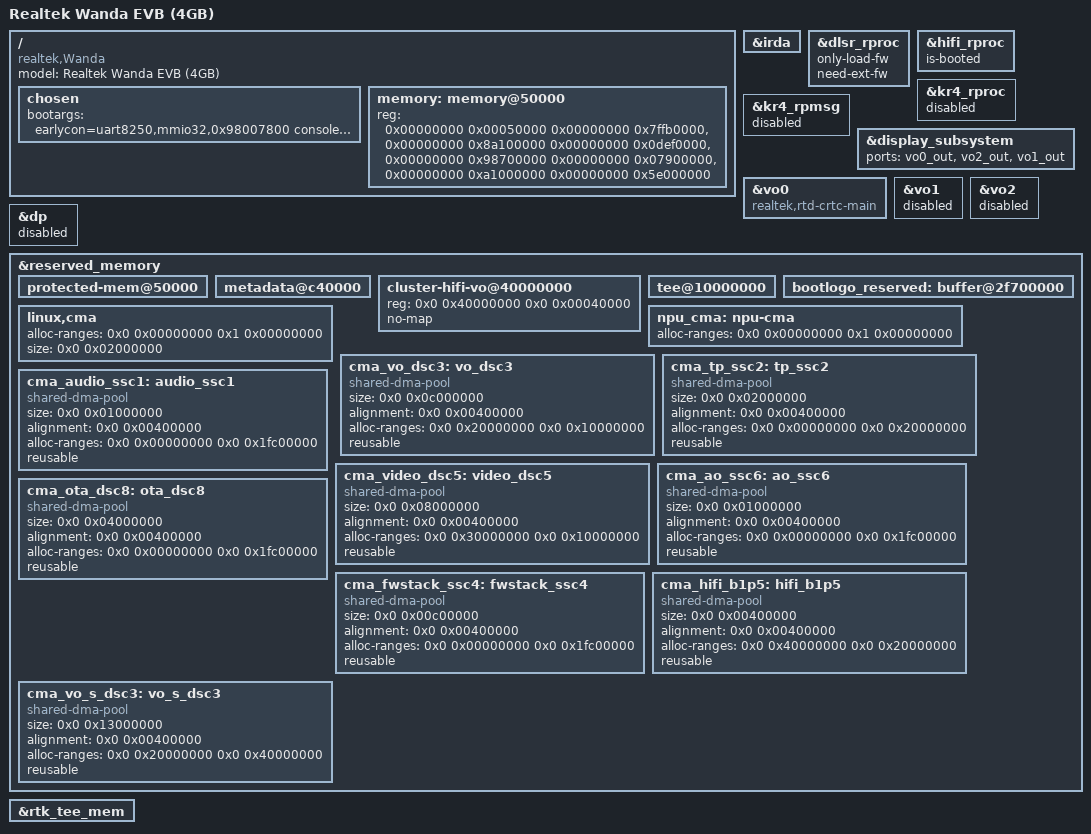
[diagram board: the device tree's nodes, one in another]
// SPDX-License-Identifier: (GPL-2.0-or-later OR BSD-2-Clause)
/*
 * Realtek RTD1635S Wanda EVB
 *
 * Copyright (c) 2025 Realtek Semiconductor Corp.
 */

/dts-v1/;

#include "rtd1635s-wanda.dtsi"

/ {
	compatible = "realtek,Wanda", "realtek,rtd1635s";
	model = "Realtek Wanda EVB (4GB)";
	chosen {
		bootargs = "earlycon=uart8250,mmio32,0x98007800 console=ttyS0,460800 8250.nr_uarts=2 init=/init loglevel=8 max_loop=64 loop.max_part=7 firmware_class.path=/vendor/firmware/,/vendor/av_fw";
	};

	memory: memory@50000 {
		device_type = "memory";
		reg = <0x00000000 0x00050000 0x00000000 0x7ffb0000>,
		      <0x00000000 0x8a100000 0x00000000 0x0def0000>,
		      <0x00000000 0x98700000 0x00000000 0x07900000>,
		      <0x00000000 0xa1000000 0x00000000 0x5e000000>;
	};
};

&irda {
	status = "okay";
};

&dlsr_rproc {
	only-load-fw;
	need-ext-fw;
	status = "okay";
};

&hifi_rproc {
	is-booted;
	status = "okay";
};

&kr4_rproc {
	status = "disabled";
};

&kr4_rpmsg {
	status = "disabled";
};

&display_subsystem {
	status = "okay";
	ports = <&vo0_out>, <&vo2_out>, <&vo1_out>;
};

&vo0 {
	compatible = "realtek,rtd-crtc-main";
	status = "okay";
};

&vo1 {
	status = "disabled";
};

&vo2 {
	status = "disabled";
};

&dp {
	status = "disabled";
};

&reserved_memory {
	protected-mem@50000 {
		status = "okay";
	};

	metadata@c40000 {
		status = "okay";
	};

	cluster-hifi-vo@40000000 {
		reg = <0x0 0x40000000 0x0 0x00040000>;  /* Cluster to Hifi vo 256kb */
		no-map;
	};

	tee@10000000 {
		status = "okay";
	};

	bootlogo_reserved: buffer@2f700000 {
		status = "okay";
	};

	linux,cma {
		alloc-ranges=<0x0 0x00000000 0x1 0x00000000>;
		size = <0x0 0x02000000>; /* 32M */
	};

	npu_cma: npu-cma {
		alloc-ranges=<0x0 0x00000000 0x1 0x00000000>;
		status = "okay";
	};

	cma_vo_dsc3:vo_dsc3 {
		compatible = "shared-dma-pool";
		size = <0x0 0x0c000000>;		    /* 192M */
		alignment = <0x0 0x00400000>;

		/* Avoid crossing A/VCPU PA2VA per 512M boundary */
		/* Avoid allocating 0x1fc00000 ~ 0x1fc00fff to LX CPU (A/VCPU/VE3) */
		alloc-ranges=<0x0 0x20000000 0x0 0x10000000>;
		reusable;
	};

	cma_tp_ssc2:tp_ssc2 {
		compatible = "shared-dma-pool";
		size = <0x0 0x02000000>;		    /* 32M */
		alignment = <0x0 0x00400000>;
		alloc-ranges=<0x0 0x00000000 0x0 0x20000000>;
		reusable;
	};

	cma_audio_ssc1:audio_ssc1 {
		compatible = "shared-dma-pool";
		size = <0x0 0x01000000>;		    /* 16M */
		alignment = <0x0 0x00400000>;

		/* Avoid crossing A/VCPU PA2VA per 512M boundary */
		/* Avoid allocating 0x1fc00000 ~ 0x1fc00fff to LX CPU (A/VCPU/VE3) */
		alloc-ranges=<0x0 0x00000000 0x0 0x1fc00000>;
		reusable;
	};

	cma_video_dsc5:video_dsc5 {
		compatible = "shared-dma-pool";
		size = <0x0 0x08000000>;		    /* 128M */
		alignment = <0x0 0x00400000>;

		/* Avoid crossing A/VCPU PA2VA per 512M boundary */
		/* Avoid allocating 0x1fc00000 ~ 0x1fc00fff to LX CPU (A/VCPU/VE3) */
		alloc-ranges=<0x0 0x30000000 0x0 0x10000000>;
		reusable;
	};

	cma_ao_ssc6:ao_ssc6 {
		compatible = "shared-dma-pool";
		size = <0x0 0x01000000>;		    /* 16M */
		alignment = <0x0 0x00400000>;

		/* Avoid crossing A/VCPU PA2VA per 512M boundary */
		/* Avoid allocating 0x1fc00000 ~ 0x1fc00fff to LX CPU (A/VCPU/VE3) */
		alloc-ranges=<0x0 0x00000000 0x0 0x1fc00000>;
		reusable;
	};

	cma_ota_dsc8:ota_dsc8 {
		compatible = "shared-dma-pool";
		size = <0x0 0x04000000>;		    /* 64M */
		alignment = <0x0 0x00400000>;

		/* Avoid crossing A/VCPU PA2VA per 512M boundary */
		/* Avoid allocating 0x1fc00000 ~ 0x1fc00fff to LX CPU (A/VCPU/VE3) */
		alloc-ranges=<0x0 0x00000000 0x0 0x1fc00000>;
		reusable;
	};

	cma_fwstack_ssc4:fwstack_ssc4 {
		compatible = "shared-dma-pool";
		size = <0x0 0x00c00000>;		    /* 12M */
		alignment = <0x0 0x00400000>;

		/* Avoid crossing A/VCPU PA2VA per 512M boundary */
		/* Avoid allocating 0x1fc00000 ~ 0x1fc00fff to LX CPU (A/VCPU/VE3) */
		alloc-ranges=<0x0 0x00000000 0x0 0x1fc00000>;
		reusable;
	};

	cma_hifi_b1p5:hifi_b1p5 {
		compatible = "shared-dma-pool";
		size = <0x0 0x00400000>;		    /* 4M */
		alignment = <0x0 0x00400000>;
		alloc-ranges=<0x0 0x40000000 0x0 0x20000000>;
		reusable;
	};

	cma_vo_s_dsc3:vo_s_dsc3 {
		compatible = "shared-dma-pool";
		size = <0x0 0x13000000>;		    /* 304M */
		alignment = <0x0 0x00400000>;
		alloc-ranges=<0x0 0x20000000 0x0 0x40000000>;
		reusable;
	};

	/delete-node/linux,cma_1;
	/delete-node/linux,cma_2;
	/delete-node/bl31-mem@10001000;
};

&rtk_tee_mem {
	status = "okay";
};
